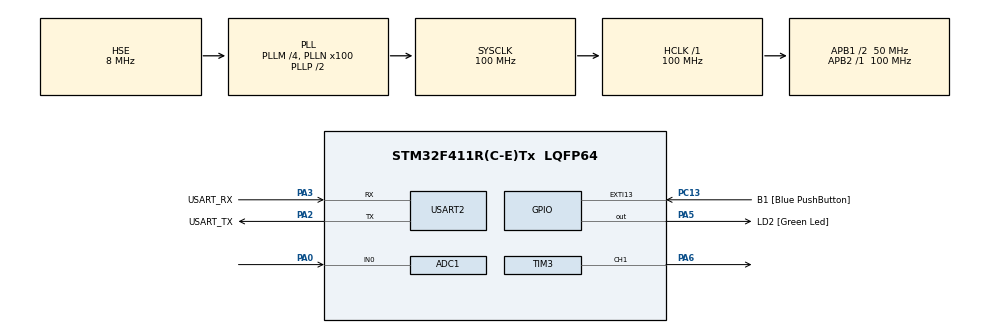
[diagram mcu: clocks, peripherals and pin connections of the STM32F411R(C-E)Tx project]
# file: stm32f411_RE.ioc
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ADC1.Channel-1\#ChannelRegularConversion=ADC_CHANNEL_0
ADC1.ClockPrescaler=ADC_CLOCK_SYNC_PCLK_DIV4
ADC1.NbrOfConversionFlag=1
ADC1.Rank-1\#ChannelRegularConversion=1
ADC1.SamplingTime-1\#ChannelRegularConversion=ADC_SAMPLETIME_84CYCLES
ADC1.master=1
FREERTOS.Queues01=myQueue01,16,uint16_t,0,Dynamic,NULL,NULL
FREERTOS.Tasks01=defaultTask,24,128,StartDefaultTask,Default,NULL,Dynamic,NULL,NULL;myTask02,8,128,uart,Default,NULL,Dynamic,NULL,NULL;myTask03,40,128,StartTask03,Default,NULL,Dynamic,NULL,NULL;myTask04,8,128,StartTask04,Default,NULL,Dynamic,NULL,NULL
FREERTOS.configUSE_NEWLIB_REENTRANT=1
Mcu.Family=STM32F4
Mcu.Name=STM32F411R(C-E)Tx
Mcu.Package=LQFP64
NVIC.EXTI15_10_IRQn=true\:5\:0\:false\:false\:true\:true\:true\:true\:true
NVIC.PriorityGroup=NVIC_PRIORITYGROUP_4
NVIC.TIM1_TRG_COM_TIM11_IRQn=true\:5\:0\:false\:false\:true\:false\:false\:true\:true
NVIC.TIM2_IRQn=true\:5\:0\:false\:false\:true\:true\:true\:true\:true
NVIC.TimeBase=TIM1_TRG_COM_TIM11_IRQn
NVIC.TimeBaseIP=TIM11
NVIC.USART2_IRQn=true\:5\:0\:false\:false\:true\:true\:true\:true\:true
PA0-WKUP.Signal=ADCx_IN0
PA13.GPIO_Label=TMS
PA13.Mode=Serial_Wire
PA13.Signal=SYS_JTMS-SWDIO
PA14.GPIO_Label=TCK
PA14.Mode=Serial_Wire
PA14.Signal=SYS_JTCK-SWCLK
PA2.GPIO_Label=USART_TX
PA2.Mode=Asynchronous
PA2.Signal=USART2_TX
PA3.GPIO_Label=USART_RX
PA3.Mode=Asynchronous
PA3.Signal=USART2_RX
PA5.GPIO_Label=LD2 [Green Led]
PA5.Signal=GPIO_Output
PA6.Signal=S_TIM3_CH1
PB3.GPIO_Label=SWO
PB3.Signal=SYS_JTDO-SWO
PC13-ANTI_TAMP.GPIO_Label=B1 [Blue PushButton]
PC13-ANTI_TAMP.GPIO_ModeDefaultEXTI=GPIO_MODE_IT_FALLING
PC13-ANTI_TAMP.Signal=GPXTI13
PC14-OSC32_IN.Mode=LSE-External-Oscillator
PC14-OSC32_IN.Signal=RCC_OSC32_IN
PC15-OSC32_OUT.Mode=LSE-External-Oscillator
PC15-OSC32_OUT.Signal=RCC_OSC32_OUT
PD2.Signal=S_TIM3_ETR
PH0\ -\ OSC_IN.Mode=HSE-External-Clock-Source
PH0\ -\ OSC_IN.Signal=RCC_OSC_IN
PH1\ -\ OSC_OUT.Mode=HSE-External-Clock-Source
PH1\ -\ OSC_OUT.Signal=RCC_OSC_OUT
ProjectManager.HeapSize=0x200
ProjectManager.StackSize=0x400
ProjectManager.TargetToolchain=STM32CubeIDE
RCC.48MHZClocksFreq_Value=50000000
RCC.AHBFreq_Value=100000000
RCC.APB1CLKDivider=RCC_HCLK_DIV2
RCC.APB1Freq_Value=50000000
RCC.APB1TimFreq_Value=100000000
RCC.APB2Freq_Value=100000000
RCC.APB2TimFreq_Value=100000000
RCC.CortexFreq_Value=100000000
RCC.FLatency-AdvancedSettings=FLASH_LATENCY_3
RCC.HCLKFreq_Value=100000000
RCC.HSE_VALUE=8000000
RCC.HSI_VALUE=16000000
RCC.PLLM=4
RCC.PLLN=100
RCC.PLLSourceVirtual=RCC_PLLSOURCE_HSE
RCC.SYSCLKFreq_VALUE=100000000
RCC.SYSCLKSource=RCC_SYSCLKSOURCE_PLLCLK
RCC.VCOOutputFreq_Value=200000000
SH.ADCx_IN0.0=ADC1_IN0,IN0
SH.S_TIM3_CH1.0=TIM3_CH1,PWM Generation1 CH1
SH.S_TIM3_ETR.0=TIM3_ETR
TIM2.Period=99
TIM2.Prescaler=9999
TIM3.Channel-PWM\ Generation1\ CH1=TIM_CHANNEL_1
TIM3.Period=19999
TIM3.Prescaler=99
USART2.VirtualMode=VM_ASYNC
VP_FREERTOS_VS_CMSIS_V2.Mode=CMSIS_V2
VP_SYS_VS_tim11.Mode=TIM11
VP_TIM2_VS_ClockSourceINT.Mode=Internal
board=NUCLEO-F411RE

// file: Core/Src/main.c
/* USER CODE BEGIN Header */
/**
  ******************************************************************************
  * @file           : main.c
  * @brief          : Main program body
  ******************************************************************************
  * @attention
  *
  * Copyright (c) 2026 STMicroelectronics.
  * All rights reserved.
  *
  * This software is licensed under terms that can be found in the LICENSE file
  * in the root directory of this software component.
  * If no LICENSE file comes with this software, it is provided AS-IS.
  *
  ******************************************************************************
  */
/* USER CODE END Header */
#include "main.h"
#include "cmsis_os.h"
#include "adc.h"
#include "tim.h"
#include "usart.h"
#include "gpio.h"

/* USER CODE BEGIN Includes */
#include "ap.h"
#include "rtos_task.h"
/* USER CODE END Includes */

void SystemClock_Config(void);
void MX_FREERTOS_Init(void);

int main(void)
{

  /* MCU Configuration--------------------------------------------------------*/

  /* Reset of all peripherals, Initializes the Flash interface and the Systick. */
  HAL_Init();

  /* Configure the system clock */
  SystemClock_Config();

  /* Initialize all configured peripherals */
  MX_GPIO_Init();
  MX_USART2_UART_Init();
  MX_TIM2_Init();
  MX_TIM3_Init();
  MX_ADC1_Init();
  /* USER CODE BEGIN 2 */
  hw_init();
  ap_init();
  rtos_init();
  /* USER CODE END 2 */

  /* Init scheduler */
  osKernelInitialize();

  /* Call init function for freertos objects (in cmsis_os2.c) */
  MX_FREERTOS_Init();

  /* Start scheduler */
  osKernelStart();

  /* We should never get here as control is now taken by the scheduler */

  /* Infinite loop */
  while (1)
  {

  }
}

void SystemClock_Config(void)
{
  RCC_OscInitTypeDef RCC_OscInitStruct = {0};
  RCC_ClkInitTypeDef RCC_ClkInitStruct = {0};

  /** Configure the main internal regulator output voltage
  */
  __HAL_RCC_PWR_CLK_ENABLE();
  __HAL_PWR_VOLTAGESCALING_CONFIG(PWR_REGULATOR_VOLTAGE_SCALE1);

  /** Initializes the RCC Oscillators according to the specified parameters
  * in the RCC_OscInitTypeDef structure.
  */
  RCC_OscInitStruct.OscillatorType = RCC_OSCILLATORTYPE_HSE;
  RCC_OscInitStruct.HSEState = RCC_HSE_BYPASS;
  RCC_OscInitStruct.PLL.PLLState = RCC_PLL_ON;
  RCC_OscInitStruct.PLL.PLLSource = RCC_PLLSOURCE_HSE;
  RCC_OscInitStruct.PLL.PLLM = 4;
  RCC_OscInitStruct.PLL.PLLN = 100;
  RCC_OscInitStruct.PLL.PLLP = RCC_PLLP_DIV2;
  RCC_OscInitStruct.PLL.PLLQ = 4;
  if (HAL_RCC_OscConfig(&RCC_OscInitStruct) != HAL_OK)
  {
    Error_Handler();
  }

  /** Initializes the CPU, AHB and APB buses clocks
  */
  RCC_ClkInitStruct.ClockType = RCC_CLOCKTYPE_HCLK|RCC_CLOCKTYPE_SYSCLK
                              |RCC_CLOCKTYPE_PCLK1|RCC_CLOCKTYPE_PCLK2;
  RCC_ClkInitStruct.SYSCLKSource = RCC_SYSCLKSOURCE_PLLCLK;
  RCC_ClkInitStruct.AHBCLKDivider = RCC_SYSCLK_DIV1;
  RCC_ClkInitStruct.APB1CLKDivider = RCC_HCLK_DIV2;
  RCC_ClkInitStruct.APB2CLKDivider = RCC_HCLK_DIV1;

  if (HAL_RCC_ClockConfig(&RCC_ClkInitStruct, FLASH_LATENCY_3) != HAL_OK)
  {
    Error_Handler();
  }
}

void HAL_TIM_PeriodElapsedCallback(TIM_HandleTypeDef *htim)
{
  if (htim->Instance == TIM11) {
    HAL_IncTick();
  }
  /* USER CODE BEGIN Callback 1 */
  else{
	  hw_TIM_PeriodElapsedCallback(htim);}
  /* USER CODE END Callback 1 */
}

void Error_Handler(void)
{
  __disable_irq();
  while (1)
  {
  }
}

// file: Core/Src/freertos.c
/* USER CODE BEGIN Header */
/**
  ******************************************************************************
  * File Name          : freertos.c
  * Description        : Code for freertos applications
  ******************************************************************************
  * @attention
  *
  * Copyright (c) 2026 STMicroelectronics.
  * All rights reserved.
  *
  * This software is licensed under terms that can be found in the LICENSE file
  * in the root directory of this software component.
  * If no LICENSE file comes with this software, it is provided AS-IS.
  *
  ******************************************************************************
  */
/* USER CODE END Header */

#include "FreeRTOS.h"
#include "task.h"
#include "main.h"
#include "cmsis_os.h"

/* USER CODE BEGIN Includes */
#include "ap.h"

#include "../../rtos/rtos_task.h"
/* USER CODE END Includes */

/* Definitions for defaultTask */
osThreadId_t defaultTaskHandle;
const osThreadAttr_t defaultTask_attributes = {
  .name = "defaultTask",
  .stack_size = 128 * 4,
  .priority = (osPriority_t) osPriorityNormal,
};
/* Definitions for myTask02 */
osThreadId_t myTask02Handle;
const osThreadAttr_t myTask02_attributes = {
  .name = "myTask02",
  .stack_size = 128 * 4,
  .priority = (osPriority_t) osPriorityLow,
};
/* Definitions for myTask03 */
osThreadId_t myTask03Handle;
const osThreadAttr_t myTask03_attributes = {
  .name = "myTask03",
  .stack_size = 128 * 4,
  .priority = (osPriority_t) osPriorityHigh,
};
/* Definitions for myTask04 */
osThreadId_t myTask04Handle;
const osThreadAttr_t myTask04_attributes = {
  .name = "myTask04",
  .stack_size = 128 * 4,
  .priority = (osPriority_t) osPriorityLow,
};
/* Definitions for myQueue01 */
osMessageQueueId_t myQueue01Handle;
const osMessageQueueAttr_t myQueue01_attributes = {
  .name = "myQueue01"
};

void StartDefaultTask(void *argument);
void uart(void *argument);
void StartTask03(void *argument);
void StartTask04(void *argument);

void MX_FREERTOS_Init(void); /* (MISRA C 2004 rule 8.1) */

void MX_FREERTOS_Init(void) {

  /* Create the queue(s) */
  /* creation of myQueue01 */
  myQueue01Handle = osMessageQueueNew (16, sizeof(uint16_t), &myQueue01_attributes);

  /* Create the thread(s) */
  /* creation of defaultTask */
  defaultTaskHandle = osThreadNew(StartDefaultTask, NULL, &defaultTask_attributes);

  /* creation of myTask02 */
  myTask02Handle = osThreadNew(uart, NULL, &myTask02_attributes);

  /* creation of myTask03 */
  myTask03Handle = osThreadNew(StartTask03, NULL, &myTask03_attributes);

  /* creation of myTask04 */
  myTask04Handle = osThreadNew(StartTask04, NULL, &myTask04_attributes);

}

void StartDefaultTask(void *argument)
{
  /* USER CODE BEGIN StartDefaultTask */
  /* Infinite loop */
  for(;;)
  {
    stopwatch_task();
  }
  /* USER CODE END StartDefaultTask */
}

void uart(void *argument)
{
  /* USER CODE BEGIN uart */
  /* Infinite loop */
  for(;;)
  {
	  uart_cmd_task();
  }
  /* USER CODE END uart */
}

void StartTask03(void *argument)
{
  /* USER CODE BEGIN StartTask03 */
  /* Infinite loop */
  for(;;)
  {
	  servo_motor_task();
  }
  /* USER CODE END StartTask03 */
}

void StartTask04(void *argument)
{
  /* USER CODE BEGIN StartTask04 */
  /* Infinite loop */
  for(;;)
  {
	 smart_blind_task();
  }
  /* USER CODE END StartTask04 */
}
